# GD32F4xx register map
File version: 1.0
CPU: CM4 r0p1, little endian, MPU, FPU, 4 interrupt priority bits
Registers are 32-bit, read-write, reset 0x0 unless marked. A register's access mark holds for its fields unless they carry their own. Offsets are from the block's base; [hi:lo] are bit positions.

## IPA — Image processing accelerator
Base 0x4002B000
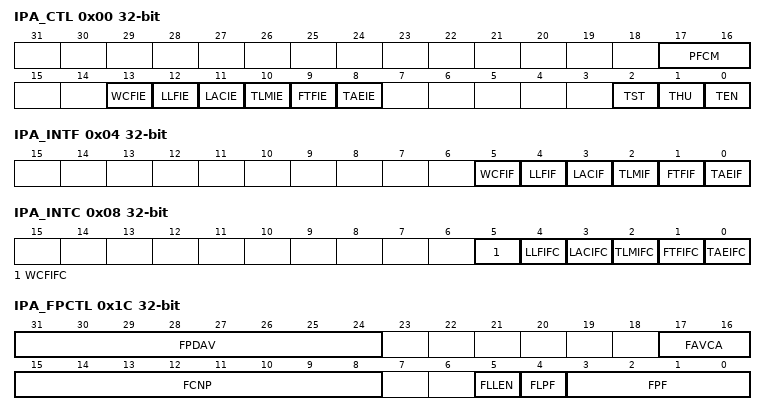
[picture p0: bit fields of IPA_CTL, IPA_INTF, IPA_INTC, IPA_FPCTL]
0x00 IPA_CTL — Control register
  [17:16] PFCM — Pixel format convert mode
  [13] WCFIE — Enable bit for wrong configuration interrupt
  [12] LLFIE — Enable bit for LUT loading finish interrupt
  [11] LACIE — Enable bit for LUT access conflict interrupt
  [10] TLMIE — Enable bit for transfer line mark interrupt
  [9] FTFIE — Enable bit for full transfer finish interrupt
  [8] TAEIE — Enable bit for transfer access error interrupt
  [2] TST — Transfer stop
  [1] THU — Transfer hang up
  [0] TEN — Transfer enable
0x04 IPA_INTF ro — Interrupt flag register
  [5] WCFIF — Wrong configuration interrupt flag
  [4] LLFIF — LUT loading finish interrupt flag
  [3] LACIF — LUT access conflict interrupt flag
  [2] TLMIF — Transfer line mark interrupt flag
  [1] FTFIF — Full transfer finish interrupt flag
  [0] TAEIF — Transfer access error interrupt flag
0x08 IPA_INTC — Interrupt flag clear register
  [5] WCFIFC — Clear bit for wrong configuration interrupt flag
  [4] LLFIFC — Clear bit for LUT loading finish interrupt flag
  [3] LACIFC — Clear bit for LUT access conflict interrupt flag
  [2] TLMIFC — Clear bit for transfer line mark interrupt flag
  [1] FTFIFC — Clear bit for full transfer finish interrupt flag
  [0] TAEIFC — Clear bit for transfer access error interrupt flag
0x0C IPA_FMADDR — Foreground memory base address register
  [31:0] FMADDR — Foreground memory base address
0x10 IPA_FLOFF — Foreground line offset register
  [13:0] FLOFF — Foreground line offset
0x14 IPA_BMADDR — Background memory base address register
  [31:0] BMADDR — Background memory base address
0x18 IPA_BLOFF — Background line offset register
  [13:0] BLOFF — Background line offset
0x1C IPA_FPCTL — Foreground pixel control register
  [31:24] FPDAV — Foreground pre- defined alpha value
  [17:16] FAVCA — Foreground alpha value calculation algorithm
  [15:8] FCNP — Foreground LUT number of pixel
  [5] FLLEN — Foreground LUT loading enable
  [4] FLPF — Foreground LUT pixel format
  [3:0] FPF — Foreground pixel format
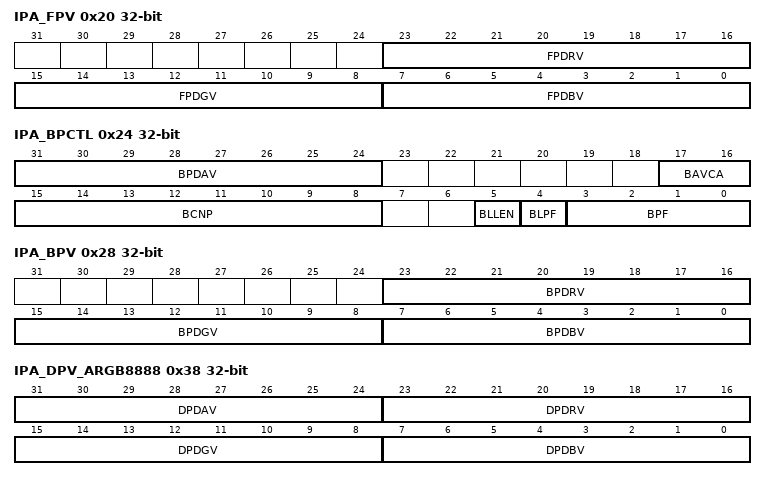
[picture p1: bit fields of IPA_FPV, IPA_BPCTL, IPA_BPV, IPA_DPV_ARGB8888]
0x20 IPA_FPV — Foreground pixel value register
  [23:16] FPDRV — Foreground pre-defined red value
  [15:8] FPDGV — Foreground pre-defined green value
  [7:0] FPDBV — Foreground pre-defined blue value
0x24 IPA_BPCTL — Background pixel control register
  [31:24] BPDAV — Background pre- defined alpha value
  [17:16] BAVCA — Background alpha value calculation algorithm
  [15:8] BCNP — Background LUT number of pixel
  [5] BLLEN — Background LUT loading enable
  [4] BLPF — Background LUT pixel format
  [3:0] BPF — Background pixel format
0x28 IPA_BPV — Background pixel value register
  [23:16] BPDRV — Background pre-defined red value
  [15:8] BPDGV — Background pre-defined green value
  [7:0] BPDBV — Background pre-defined blue value
0x2C IPA_FLMADDR — Foreground LUT memory base address register
  [31:0] FLMADDR — Foreground LUT memory base address
0x30 IPA_BLMADDR — Background LUT memory base address register
  [31:0] BLMADDR — Background LUT memory base address
0x34 IPA_DPCTL — Destination pixel control register
  [2:0] DPF — Destination pixel format
0x38 IPA_DPV_ARGB8888 — Destination pixel value register(When the destination pixel format is ARGB8888)
  [31:24] DPDAV — Destination pre-defined alpha value
  [23:16] DPDRV — Destination pre-defined red value
  [15:8] DPDGV — Destination pre-defined green value
  [7:0] DPDBV — Destination pre-defined blue value
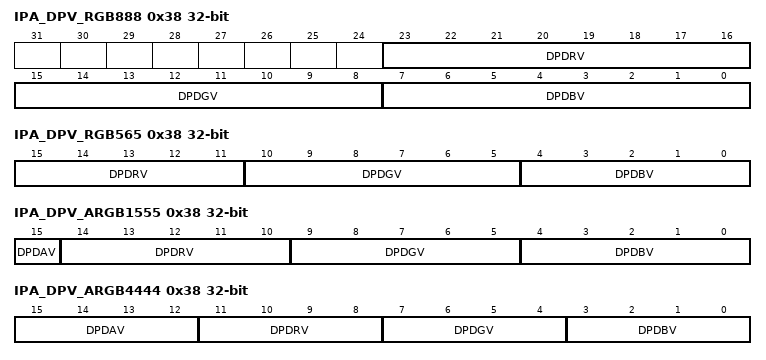
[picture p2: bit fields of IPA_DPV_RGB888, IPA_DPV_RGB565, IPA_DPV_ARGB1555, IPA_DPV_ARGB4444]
0x38 IPA_DPV_RGB888 (alternate view of IPA_DPV_ARGB8888) — Destination pixel value register(When the destination pixel format is RGB888)
  [23:16] DPDRV — Destination pre-defined red value
  [15:8] DPDGV — Destination pre-defined green value
  [7:0] DPDBV — Destination pre-defined blue value
0x38 IPA_DPV_RGB565 (alternate view of IPA_DPV_ARGB8888) — Destination pixel value register(When the destination pixel format is RGB565)
  [15:11] DPDRV — Destination pre-defined red value
  [10:5] DPDGV — Destination pre-defined green value
  [4:0] DPDBV — Destination pre-defined blue value
0x38 IPA_DPV_ARGB1555 (alternate view of IPA_DPV_ARGB8888) — Destination pixel value register(When the destination pixel format is ARGB1555)
  [15] DPDAV — Destination pre-defined alpha value
  [14:10] DPDRV — Destination pre-defined red value
  [9:5] DPDGV — Destination pre-defined green value
  [4:0] DPDBV — Destination pre-defined blue value
0x38 IPA_DPV_ARGB4444 (alternate view of IPA_DPV_ARGB8888) — Destination pixel value register(When the destination pixel format is ARGB4444,)
  [15:12] DPDAV — Destination pre-defined alpha value
  [11:8] DPDRV — Destination pre-defined red value
  [7:4] DPDGV — Destination pre-defined green value
  [3:0] DPDBV — Destination pre-defined blue value
0x3C IPA_DMADDR — Destination memory base address register
  [31:0] DMADDR — Destination memory base address
0x40 IPA_DLOFF — Destination line offset register
  [13:0] DLOFF — Destination line offset
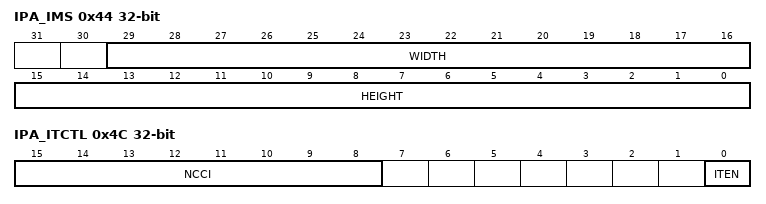
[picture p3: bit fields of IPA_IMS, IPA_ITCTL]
0x44 IPA_IMS — Image size register
  [29:16] WIDTH — Width of the image to be processed
  [15:0] HEIGHT — Height of the image to be processed
0x48 IPA_LM — Line mark register
  [15:0] LM — line mark
0x4C IPA_ITCTL — Inter-timer control register
  [15:8] NCCI — Number of clock cycles interval
  [0] ITEN — Inter-timer enable
